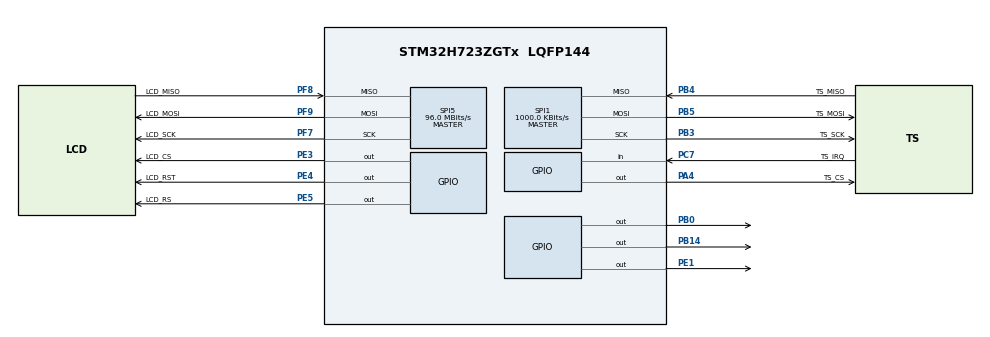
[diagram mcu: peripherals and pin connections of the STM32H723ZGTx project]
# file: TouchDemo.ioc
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CORTEX_M7.default_mode_Activation=1
Mcu.Family=STM32H7
Mcu.Name=STM32H723ZGTx
Mcu.Package=LQFP144
NUCLEO-H723ZG.BUTTON=2
NUCLEO-H723ZG.LD1=true
NUCLEO-H723ZG.LD2=true
NUCLEO-H723ZG.LD3=true
NUCLEO-H723ZG.VCP=true
NVIC.PriorityGroup=NVIC_PRIORITYGROUP_4
PA13(JTMS/SWDIO).GPIO_Label=SWDIO
PA13(JTMS/SWDIO).Signal=DEBUG_JTMS-SWDIO
PA14(JTCK/SWCLK).GPIO_Label=SWCLK
PA14(JTCK/SWCLK).Signal=DEBUG_JTCK-SWCLK
PA4.GPIO_Label=TS_CS
PA4.GPIO_Speed=GPIO_SPEED_FREQ_VERY_HIGH
PA4.PinState=GPIO_PIN_SET
PA4.Signal=GPIO_Output
PB0.Signal=GPIO_Output
PB14.Signal=GPIO_Output
PB3(JTDO/TRACESWO).GPIO_Label=TS_SCK
PB3(JTDO/TRACESWO).Mode=Full_Duplex_Master
PB3(JTDO/TRACESWO).Signal=SPI1_SCK
PB4(NJTRST).GPIO_Label=TS_MISO
PB4(NJTRST).Mode=Full_Duplex_Master
PB4(NJTRST).Signal=SPI1_MISO
PB5.GPIO_Label=TS_MOSI
PB5.Mode=Full_Duplex_Master
PB5.Signal=SPI1_MOSI
PC14-OSC32_IN.Signal=RCC_OSC32_IN
PC15-OSC32_OUT.Signal=RCC_OSC32_OUT
PC7.GPIO_Label=TS_IRQ
PC7.Signal=GPIO_Input
PD8.Signal=USART3_TX
PD9.Signal=USART3_RX
PE1.Signal=GPIO_Output
PE3.GPIO_Label=LCD_CS
PE3.GPIO_Speed=GPIO_SPEED_FREQ_VERY_HIGH
PE3.PinState=GPIO_PIN_SET
PE3.Signal=GPIO_Output
PE4.GPIO_Label=LCD_RST
PE4.PinState=GPIO_PIN_SET
PE4.Signal=GPIO_Output
PE5.GPIO_Label=LCD_RS
PE5.GPIO_Speed=GPIO_SPEED_FREQ_VERY_HIGH
PE5.Signal=GPIO_Output
PF7.GPIO_Label=LCD_SCK
PF7.GPIO_Speed=GPIO_SPEED_FREQ_VERY_HIGH
PF7.Mode=Full_Duplex_Master
PF7.Signal=SPI5_SCK
PF8.GPIO_Label=LCD_MISO
PF8.GPIO_Speed=GPIO_SPEED_FREQ_VERY_HIGH
PF8.Mode=Full_Duplex_Master
PF8.Signal=SPI5_MISO
PF9.GPIO_Label=LCD_MOSI
PF9.GPIO_Speed=GPIO_SPEED_FREQ_VERY_HIGH
PF9.Mode=Full_Duplex_Master
PF9.Signal=SPI5_MOSI
ProjectManager.HeapSize=0x200
ProjectManager.StackSize=0x400
ProjectManager.TargetToolchain=STM32CubeIDE
RCC.ADCFreq_Value=192000000
RCC.APB1Freq_Value=125000000
RCC.APB2Freq_Value=125000000
RCC.APB3Freq_Value=125000000
RCC.APB4Freq_Value=125000000
RCC.CortexFreq_Value=500000000
RCC.D1PPRE=RCC_APB3_DIV2
RCC.D2PPRE1=RCC_APB1_DIV2
RCC.D2PPRE2=RCC_APB2_DIV2
RCC.D3PPRE=RCC_APB4_DIV2
RCC.DIVM1=4
RCC.DIVM2=4
RCC.DIVN1=31
RCC.DIVN2=12
RCC.DIVP1=1
RCC.DIVP2=1
RCC.DIVQ2=1
RCC.HCLKFreq_Value=250000000
RCC.HPRE=RCC_HCLK_DIV2
RCC.HSE_VALUE=8000000
RCC.PLL2FRACN=0
RCC.PLLFRACN=2048
RCC.SPI123CLockSelection=RCC_SPI123CLKSOURCE_CLKP
RCC.SYSCLKFreq_VALUE=500000000
RCC.SYSCLKSource=RCC_SYSCLKSOURCE_PLLCLK
RCC.Spi45ClockSelection=RCC_SPI45CLKSOURCE_PLL2
RCC.USBCLockSelection=RCC_USBCLKSOURCE_HSI48
RCC.USBFreq_Value=48000000
SPI1.BaudRatePrescaler=SPI_BAUDRATEPRESCALER_64
SPI1.CalculateBaudRate=1000.0 KBits/s
SPI1.DataSize=SPI_DATASIZE_8BIT
SPI1.Direction=SPI_DIRECTION_2LINES
SPI1.Mode=SPI_MODE_MASTER
SPI1.VirtualType=VM_MASTER
SPI5.BaudRatePrescaler=SPI_BAUDRATEPRESCALER_2
SPI5.CalculateBaudRate=96.0 MBits/s
SPI5.DataSize=SPI_DATASIZE_16BIT
SPI5.Direction=SPI_DIRECTION_2LINES
SPI5.FirstBit=SPI_FIRSTBIT_MSB
SPI5.Mode=SPI_MODE_MASTER
SPI5.NSSPMode=SPI_NSS_PULSE_DISABLE
SPI5.VirtualType=VM_MASTER
VP_MEMORYMAP_VS_MEMORYMAP.Mode=CurAppReg
VP_NUCLEO-H723ZG_VS_BSP_COMMON.Mode=COMMON
board=NUCLEO-H723ZG

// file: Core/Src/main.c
/* USER CODE BEGIN Header */
/**
  ******************************************************************************
  * @file           : main.c
  * @brief          : Main program body
  ******************************************************************************
  * @attention
  *
  * Copyright (c) 2025 STMicroelectronics.
  * All rights reserved.
  *
  * This software is licensed under terms that can be found in the LICENSE file
  * in the root directory of this software component.
  * If no LICENSE file comes with this software, it is provided AS-IS.
  *
  ******************************************************************************
  */
/* USER CODE END Header */
#include "main.h"

COM_InitTypeDef BspCOMInit;

SPI_HandleTypeDef hspi1;
SPI_HandleTypeDef hspi5;

void SystemClock_Config(void);
void PeriphCommonClock_Config(void);
static void MPU_Config(void);
static void MX_GPIO_Init(void);
static void MX_SPI5_Init(void);
static void MX_SPI1_Init(void);
/* USER CODE BEGIN PFP */
void mainApp(void);
/* USER CODE END PFP */

int main(void)
{

  /* MPU Configuration--------------------------------------------------------*/
  MPU_Config();

  /* MCU Configuration--------------------------------------------------------*/

  /* Reset of all peripherals, Initializes the Flash interface and the Systick. */
  HAL_Init();

  /* Configure the system clock */
  SystemClock_Config();

  /* Configure the peripherals common clocks */
  PeriphCommonClock_Config();

  /* Initialize all configured peripherals */
  MX_GPIO_Init();
  MX_SPI5_Init();
  MX_SPI1_Init();

  /* Initialize leds */
  BSP_LED_Init(LED_GREEN);
  BSP_LED_Init(LED_YELLOW);
  BSP_LED_Init(LED_RED);

  /* Initialize User push-button without interrupt mode. */
  BSP_PB_Init(BUTTON_USER, BUTTON_MODE_GPIO);

  /* Initialize COM1 port (115200, 8 bits (7-bit data + 1 stop bit), no parity */
  BspCOMInit.BaudRate   = 115200;
  BspCOMInit.WordLength = COM_WORDLENGTH_8B;
  BspCOMInit.StopBits   = COM_STOPBITS_1;
  BspCOMInit.Parity     = COM_PARITY_NONE;
  BspCOMInit.HwFlowCtl  = COM_HWCONTROL_NONE;
  if (BSP_COM_Init(COM1, &BspCOMInit) != BSP_ERROR_NONE)
  {
    Error_Handler();
  }

  /* Infinite loop */
  /* USER CODE BEGIN WHILE */
  mainApp();
  while (1)
  {

    /* USER CODE END WHILE */

  }
}

void SystemClock_Config(void)
{
  RCC_OscInitTypeDef RCC_OscInitStruct = {0};
  RCC_ClkInitTypeDef RCC_ClkInitStruct = {0};

  /** Supply configuration update enable
  */
  HAL_PWREx_ConfigSupply(PWR_LDO_SUPPLY);

  /** Configure the main internal regulator output voltage
  */
  __HAL_PWR_VOLTAGESCALING_CONFIG(PWR_REGULATOR_VOLTAGE_SCALE0);

  while(!__HAL_PWR_GET_FLAG(PWR_FLAG_VOSRDY)) {}

  /** Initializes the RCC Oscillators according to the specified parameters
  * in the RCC_OscInitTypeDef structure.
  */
  RCC_OscInitStruct.OscillatorType = RCC_OSCILLATORTYPE_HSI;
  RCC_OscInitStruct.HSIState = RCC_HSI_DIV1;
  RCC_OscInitStruct.HSICalibrationValue = 64;
  RCC_OscInitStruct.PLL.PLLState = RCC_PLL_ON;
  RCC_OscInitStruct.PLL.PLLSource = RCC_PLLSOURCE_HSI;
  RCC_OscInitStruct.PLL.PLLM = 4;
  RCC_OscInitStruct.PLL.PLLN = 31;
  RCC_OscInitStruct.PLL.PLLP = 1;
  RCC_OscInitStruct.PLL.PLLQ = 2;
  RCC_OscInitStruct.PLL.PLLR = 2;
  RCC_OscInitStruct.PLL.PLLRGE = RCC_PLL1VCIRANGE_3;
  RCC_OscInitStruct.PLL.PLLVCOSEL = RCC_PLL1VCOWIDE;
  RCC_OscInitStruct.PLL.PLLFRACN = 2048;
  if (HAL_RCC_OscConfig(&RCC_OscInitStruct) != HAL_OK)
  {
    Error_Handler();
  }

  /** Initializes the CPU, AHB and APB buses clocks
  */
  RCC_ClkInitStruct.ClockType = RCC_CLOCKTYPE_HCLK|RCC_CLOCKTYPE_SYSCLK
                              |RCC_CLOCKTYPE_PCLK1|RCC_CLOCKTYPE_PCLK2
                              |RCC_CLOCKTYPE_D3PCLK1|RCC_CLOCKTYPE_D1PCLK1;
  RCC_ClkInitStruct.SYSCLKSource = RCC_SYSCLKSOURCE_PLLCLK;
  RCC_ClkInitStruct.SYSCLKDivider = RCC_SYSCLK_DIV1;
  RCC_ClkInitStruct.AHBCLKDivider = RCC_HCLK_DIV2;
  RCC_ClkInitStruct.APB3CLKDivider = RCC_APB3_DIV2;
  RCC_ClkInitStruct.APB1CLKDivider = RCC_APB1_DIV2;
  RCC_ClkInitStruct.APB2CLKDivider = RCC_APB2_DIV2;
  RCC_ClkInitStruct.APB4CLKDivider = RCC_APB4_DIV2;

  if (HAL_RCC_ClockConfig(&RCC_ClkInitStruct, FLASH_LATENCY_3) != HAL_OK)
  {
    Error_Handler();
  }
}

void PeriphCommonClock_Config(void)
{
  RCC_PeriphCLKInitTypeDef PeriphClkInitStruct = {0};

  /** Initializes the peripherals clock
  */
  PeriphClkInitStruct.PeriphClockSelection = RCC_PERIPHCLK_CKPER;
  PeriphClkInitStruct.CkperClockSelection = RCC_CLKPSOURCE_HSI;
  if (HAL_RCCEx_PeriphCLKConfig(&PeriphClkInitStruct) != HAL_OK)
  {
    Error_Handler();
  }
}

static void MX_SPI1_Init(void)
{

  /* SPI1 parameter configuration*/
  hspi1.Instance = SPI1;
  hspi1.Init.Mode = SPI_MODE_MASTER;
  hspi1.Init.Direction = SPI_DIRECTION_2LINES;
  hspi1.Init.DataSize = SPI_DATASIZE_8BIT;
  hspi1.Init.CLKPolarity = SPI_POLARITY_LOW;
  hspi1.Init.CLKPhase = SPI_PHASE_1EDGE;
  hspi1.Init.NSS = SPI_NSS_SOFT;
  hspi1.Init.BaudRatePrescaler = SPI_BAUDRATEPRESCALER_64;
  hspi1.Init.FirstBit = SPI_FIRSTBIT_MSB;
  hspi1.Init.TIMode = SPI_TIMODE_DISABLE;
  hspi1.Init.CRCCalculation = SPI_CRCCALCULATION_DISABLE;
  hspi1.Init.CRCPolynomial = 0x0;
  hspi1.Init.NSSPMode = SPI_NSS_PULSE_ENABLE;
  hspi1.Init.NSSPolarity = SPI_NSS_POLARITY_LOW;
  hspi1.Init.FifoThreshold = SPI_FIFO_THRESHOLD_01DATA;
  hspi1.Init.TxCRCInitializationPattern = SPI_CRC_INITIALIZATION_ALL_ZERO_PATTERN;
  hspi1.Init.RxCRCInitializationPattern = SPI_CRC_INITIALIZATION_ALL_ZERO_PATTERN;
  hspi1.Init.MasterSSIdleness = SPI_MASTER_SS_IDLENESS_00CYCLE;
  hspi1.Init.MasterInterDataIdleness = SPI_MASTER_INTERDATA_IDLENESS_00CYCLE;
  hspi1.Init.MasterReceiverAutoSusp = SPI_MASTER_RX_AUTOSUSP_DISABLE;
  hspi1.Init.MasterKeepIOState = SPI_MASTER_KEEP_IO_STATE_DISABLE;
  hspi1.Init.IOSwap = SPI_IO_SWAP_DISABLE;
  if (HAL_SPI_Init(&hspi1) != HAL_OK)
  {
    Error_Handler();
  }

}

static void MX_SPI5_Init(void)
{

  /* SPI5 parameter configuration*/
  hspi5.Instance = SPI5;
  hspi5.Init.Mode = SPI_MODE_MASTER;
  hspi5.Init.Direction = SPI_DIRECTION_2LINES;
  hspi5.Init.DataSize = SPI_DATASIZE_16BIT;
  hspi5.Init.CLKPolarity = SPI_POLARITY_LOW;
  hspi5.Init.CLKPhase = SPI_PHASE_1EDGE;
  hspi5.Init.NSS = SPI_NSS_SOFT;
  hspi5.Init.BaudRatePrescaler = SPI_BAUDRATEPRESCALER_2;
  hspi5.Init.FirstBit = SPI_FIRSTBIT_MSB;
  hspi5.Init.TIMode = SPI_TIMODE_DISABLE;
  hspi5.Init.CRCCalculation = SPI_CRCCALCULATION_DISABLE;
  hspi5.Init.CRCPolynomial = 0x0;
  hspi5.Init.NSSPMode = SPI_NSS_PULSE_DISABLE;
  hspi5.Init.NSSPolarity = SPI_NSS_POLARITY_LOW;
  hspi5.Init.FifoThreshold = SPI_FIFO_THRESHOLD_01DATA;
  hspi5.Init.TxCRCInitializationPattern = SPI_CRC_INITIALIZATION_ALL_ZERO_PATTERN;
  hspi5.Init.RxCRCInitializationPattern = SPI_CRC_INITIALIZATION_ALL_ZERO_PATTERN;
  hspi5.Init.MasterSSIdleness = SPI_MASTER_SS_IDLENESS_00CYCLE;
  hspi5.Init.MasterInterDataIdleness = SPI_MASTER_INTERDATA_IDLENESS_00CYCLE;
  hspi5.Init.MasterReceiverAutoSusp = SPI_MASTER_RX_AUTOSUSP_DISABLE;
  hspi5.Init.MasterKeepIOState = SPI_MASTER_KEEP_IO_STATE_DISABLE;
  hspi5.Init.IOSwap = SPI_IO_SWAP_DISABLE;
  if (HAL_SPI_Init(&hspi5) != HAL_OK)
  {
    Error_Handler();
  }

}

static void MX_GPIO_Init(void)
{
  GPIO_InitTypeDef GPIO_InitStruct = {0};

  /* GPIO Ports Clock Enable */
  __HAL_RCC_GPIOE_CLK_ENABLE();
  __HAL_RCC_GPIOC_CLK_ENABLE();
  __HAL_RCC_GPIOF_CLK_ENABLE();
  __HAL_RCC_GPIOA_CLK_ENABLE();
  __HAL_RCC_GPIOB_CLK_ENABLE();

  /*Configure GPIO pin Output Level */
  HAL_GPIO_WritePin(GPIOE, LCD_CS_Pin|LCD_RST_Pin, GPIO_PIN_SET);

  /*Configure GPIO pin Output Level */
  HAL_GPIO_WritePin(LCD_RS_GPIO_Port, LCD_RS_Pin, GPIO_PIN_RESET);

  /*Configure GPIO pin Output Level */
  HAL_GPIO_WritePin(TS_CS_GPIO_Port, TS_CS_Pin, GPIO_PIN_SET);

  /*Configure GPIO pins : LCD_CS_Pin LCD_RS_Pin */
  GPIO_InitStruct.Pin = LCD_CS_Pin|LCD_RS_Pin;
  GPIO_InitStruct.Mode = GPIO_MODE_OUTPUT_PP;
  GPIO_InitStruct.Pull = GPIO_NOPULL;
  GPIO_InitStruct.Speed = GPIO_SPEED_FREQ_VERY_HIGH;
  HAL_GPIO_Init(GPIOE, &GPIO_InitStruct);

  /*Configure GPIO pin : LCD_RST_Pin */
  GPIO_InitStruct.Pin = LCD_RST_Pin;
  GPIO_InitStruct.Mode = GPIO_MODE_OUTPUT_PP;
  GPIO_InitStruct.Pull = GPIO_NOPULL;
  GPIO_InitStruct.Speed = GPIO_SPEED_FREQ_LOW;
  HAL_GPIO_Init(LCD_RST_GPIO_Port, &GPIO_InitStruct);

  /*Configure GPIO pin : TS_CS_Pin */
  GPIO_InitStruct.Pin = TS_CS_Pin;
  GPIO_InitStruct.Mode = GPIO_MODE_OUTPUT_PP;
  GPIO_InitStruct.Pull = GPIO_NOPULL;
  GPIO_InitStruct.Speed = GPIO_SPEED_FREQ_VERY_HIGH;
  HAL_GPIO_Init(TS_CS_GPIO_Port, &GPIO_InitStruct);

  /*Configure GPIO pin : TS_IRQ_Pin */
  GPIO_InitStruct.Pin = TS_IRQ_Pin;
  GPIO_InitStruct.Mode = GPIO_MODE_INPUT;
  GPIO_InitStruct.Pull = GPIO_NOPULL;
  HAL_GPIO_Init(TS_IRQ_GPIO_Port, &GPIO_InitStruct);

}

 /* MPU Configuration */

void MPU_Config(void)
{
  MPU_Region_InitTypeDef MPU_InitStruct = {0};

  /* Disables the MPU */
  HAL_MPU_Disable();

  /** Initializes and configures the Region and the memory to be protected
  */
  MPU_InitStruct.Enable = MPU_REGION_ENABLE;
  MPU_InitStruct.Number = MPU_REGION_NUMBER0;
  MPU_InitStruct.BaseAddress = 0x0;
  MPU_InitStruct.Size = MPU_REGION_SIZE_4GB;
  MPU_InitStruct.SubRegionDisable = 0x87;
  MPU_InitStruct.TypeExtField = MPU_TEX_LEVEL0;
  MPU_InitStruct.AccessPermission = MPU_REGION_NO_ACCESS;
  MPU_InitStruct.DisableExec = MPU_INSTRUCTION_ACCESS_DISABLE;
  MPU_InitStruct.IsShareable = MPU_ACCESS_SHAREABLE;
  MPU_InitStruct.IsCacheable = MPU_ACCESS_NOT_CACHEABLE;
  MPU_InitStruct.IsBufferable = MPU_ACCESS_NOT_BUFFERABLE;

  HAL_MPU_ConfigRegion(&MPU_InitStruct);
  /* Enables the MPU */
  HAL_MPU_Enable(MPU_PRIVILEGED_DEFAULT);

}

void Error_Handler(void)
{
  __disable_irq();
  while (1)
  {
  }
}
